AUTOSAR XML (schema 4-3-0)
# \copyright BMW AG 2015 - 2017
package /BMW/Platform/Rmh/SwComponentTypes
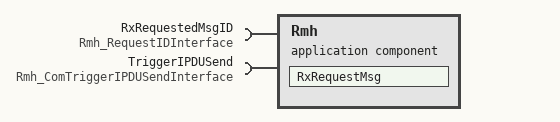
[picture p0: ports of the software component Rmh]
  application sw component type Rmh
    require port RxRequestedMsgID: nonqueued-receiver-com-spec{data-element=requestedMsgID, init-value=0xFFFF}, required-interface=Rmh_RequestIDInterface
    require port TriggerIPDUSend: required-interface=Rmh_ComTriggerIPDUSendInterface
    behavior InternalBehavior: handle-termination-and-restart=NO-SUPPORT
      data received event DataReceivedEvent: start-on-event=RxRequestMsg, data=RxRequestedMsgID.requestedMsgID
      port-api-options:
        enable-take-address=false, indirect-api=false, port=TriggerIPDUSend
        enable-take-address=false, indirect-api=false, port=RxRequestedMsgID
      runnable RxRequestMsg: symbol=Rmh_RxRequestMsg
        data-receive-point-by-arguments:
          access dra_RxRequestedMsgID: accessed-variable=RxRequestedMsgID.requestedMsgID
        sync call sscp_TriggerIPDUSend: operation=TriggerIPDUSend.Rmh_TriggerComIPDUSend, timeout=0
package /BMW/Platform/Rmh/SwcImplementations
  swc implementation Rmh_Implementation: programming-language=C, sw-version=5.0.0, vendor-id=5, behavior=InternalBehavior
    code-descriptors:
      code CodeDescriptor: artifact-descriptors=autosar-engineering-object={short-label=EngObject, category=SWSRC}
    resource consumption Ressource
